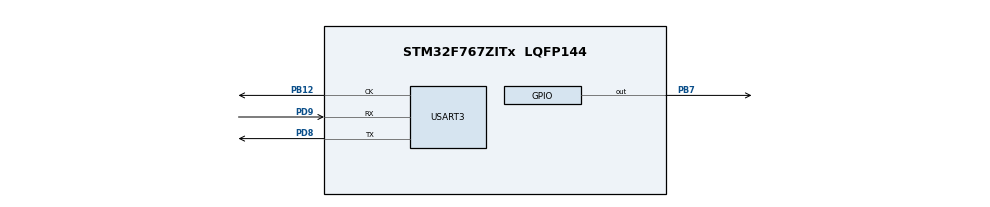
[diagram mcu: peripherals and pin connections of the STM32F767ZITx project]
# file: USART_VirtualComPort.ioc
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Mcu.Family=STM32F7
Mcu.Name=STM32F767ZITx
Mcu.Package=LQFP144
NVIC.PriorityGroup=NVIC_PRIORITYGROUP_4
PA13.Mode=Serial_Wire
PA13.Signal=SYS_JTMS-SWDIO
PA14.Mode=Serial_Wire
PA14.Signal=SYS_JTCK-SWCLK
PB12.Mode=Synchronous
PB12.Signal=USART3_CK
PB7.Signal=GPIO_Output
PD8.Mode=Synchronous
PD8.Signal=USART3_TX
PD9.Mode=Synchronous
PD9.Signal=USART3_RX
ProjectManager.HeapSize=0x200
ProjectManager.StackSize=0x400
ProjectManager.TargetToolchain=CMake
RCC.HSE_VALUE=25000000
RCC.HSI_VALUE=16000000
RCC.LSE_VALUE=32768
RCC.USBFreq_Value=96000000
RCC.VCOOutputFreq_Value=192000000
USART3.VirtualMode-Synchronous=VM_SYNC
board=custom

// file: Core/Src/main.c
/* USER CODE BEGIN Header */
/**
  ******************************************************************************
  * @file           : main.c
  * @brief          : Main program body
  ******************************************************************************
  * @author         : Jabed-Akhtar
  * @date           : 12.03.2022
  ******************************************************************************
  * Description:
  *		- LED: PB7 (for testing purpose)
  *		- USART3: 	Tx Pin -> PD8
  *					Rx Pin -> PD9
  *		- While connecting the STM32F767ZI board to PC, it will have a COM-Port,
  *		  which can be seen in Device Manager (in Window PC). Configuring USART3
  *		  and with this pins allows monitoring USART without connecting any
  *		  extra wire. Simply opening serial line with here configured USART speed
  *		  allows monitoring the messages coming through USART, for example with
  *		  tool PiTTY.
  ******************************************************************************
  */
/* USER CODE END Header */
#include "main.h"

USART_HandleTypeDef husart3;

void SystemClock_Config(void);
static void MX_GPIO_Init(void);
static void MX_USART3_Init(void);
/* USER CODE BEGIN PFP */
// global variables
char couChar[20];
/* USER CODE END PFP */

int main(void)
{

  /* MCU Configuration--------------------------------------------------------*/

  /* Reset of all peripherals, Initializes the Flash interface and the Systick. */
  HAL_Init();

  /* Configure the system clock */
  SystemClock_Config();

  /* Initialize all configured peripherals */
  MX_GPIO_Init();
  MX_USART3_Init();
  /* USER CODE BEGIN 2 */
  int cou = 0;
  /* USER CODE END 2 */

  /* Infinite loop */
  /* USER CODE BEGIN WHILE */
  while (1)
  {
    /* Sending message through USART every 1sec */
	  cou++; // increasing counter every 100oms
	  sprintf(couChar, "Counter: %d\n\r", cou);
	  HAL_USART_Transmit(&husart3, (uint8_t*)couChar, strlen(couChar), 0xFFFF);
	  HAL_GPIO_WritePin(GPIOB, GPIO_PIN_7, GPIO_PIN_SET);
	  HAL_Delay(200); // Delay of 200ms -> to turn On LED for 200 after msg through USART is sent
	  HAL_GPIO_WritePin(GPIOB, GPIO_PIN_7, GPIO_PIN_RESET);
	  HAL_Delay(800); // Delay of 800ms -> 200ms+1000ms=1sec waits till next msg through USART is sent
    /* USER CODE END WHILE */

  }
}

void SystemClock_Config(void)
{
  RCC_OscInitTypeDef RCC_OscInitStruct = {0};
  RCC_ClkInitTypeDef RCC_ClkInitStruct = {0};

  /** Configure the main internal regulator output voltage
  */
  __HAL_RCC_PWR_CLK_ENABLE();
  __HAL_PWR_VOLTAGESCALING_CONFIG(PWR_REGULATOR_VOLTAGE_SCALE3);

  /** Initializes the RCC Oscillators according to the specified parameters
  * in the RCC_OscInitTypeDef structure.
  */
  RCC_OscInitStruct.OscillatorType = RCC_OSCILLATORTYPE_HSI;
  RCC_OscInitStruct.HSIState = RCC_HSI_ON;
  RCC_OscInitStruct.HSICalibrationValue = RCC_HSICALIBRATION_DEFAULT;
  RCC_OscInitStruct.PLL.PLLState = RCC_PLL_NONE;
  if (HAL_RCC_OscConfig(&RCC_OscInitStruct) != HAL_OK)
  {
    Error_Handler();
  }

  /** Initializes the CPU, AHB and APB buses clocks
  */
  RCC_ClkInitStruct.ClockType = RCC_CLOCKTYPE_HCLK|RCC_CLOCKTYPE_SYSCLK
                              |RCC_CLOCKTYPE_PCLK1|RCC_CLOCKTYPE_PCLK2;
  RCC_ClkInitStruct.SYSCLKSource = RCC_SYSCLKSOURCE_HSI;
  RCC_ClkInitStruct.AHBCLKDivider = RCC_SYSCLK_DIV1;
  RCC_ClkInitStruct.APB1CLKDivider = RCC_HCLK_DIV1;
  RCC_ClkInitStruct.APB2CLKDivider = RCC_HCLK_DIV1;

  if (HAL_RCC_ClockConfig(&RCC_ClkInitStruct, FLASH_LATENCY_0) != HAL_OK)
  {
    Error_Handler();
  }
}

static void MX_USART3_Init(void)
{

  husart3.Instance = USART3;
  husart3.Init.BaudRate = 115200;
  husart3.Init.WordLength = USART_WORDLENGTH_8B;
  husart3.Init.StopBits = USART_STOPBITS_1;
  husart3.Init.Parity = USART_PARITY_NONE;
  husart3.Init.Mode = USART_MODE_TX_RX;
  husart3.Init.CLKPolarity = USART_POLARITY_LOW;
  husart3.Init.CLKPhase = USART_PHASE_1EDGE;
  husart3.Init.CLKLastBit = USART_LASTBIT_DISABLE;
  if (HAL_USART_Init(&husart3) != HAL_OK)
  {
    Error_Handler();
  }

}

static void MX_GPIO_Init(void)
{
  GPIO_InitTypeDef GPIO_InitStruct = {0};

  /* GPIO Ports Clock Enable */
  __HAL_RCC_GPIOB_CLK_ENABLE();
  __HAL_RCC_GPIOD_CLK_ENABLE();
  __HAL_RCC_GPIOA_CLK_ENABLE();

  /*Configure GPIO pin Output Level */
  HAL_GPIO_WritePin(GPIOB, GPIO_PIN_7, GPIO_PIN_RESET);

  /*Configure GPIO pin : PB7 */
  GPIO_InitStruct.Pin = GPIO_PIN_7;
  GPIO_InitStruct.Mode = GPIO_MODE_OUTPUT_PP;
  GPIO_InitStruct.Pull = GPIO_NOPULL;
  GPIO_InitStruct.Speed = GPIO_SPEED_FREQ_LOW;
  HAL_GPIO_Init(GPIOB, &GPIO_InitStruct);

}

void Error_Handler(void)
{
  __disable_irq();
  while (1)
  {
  }
}
